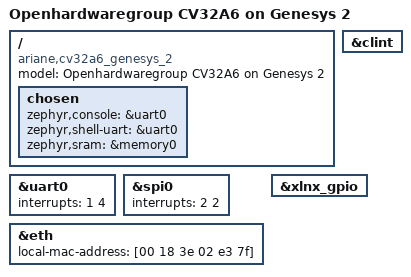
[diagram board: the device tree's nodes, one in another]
/*
 * Copyright (c) 2024 CISPA Helmholtz Center for Information Security gGmbH
 *
 * SPDX-License-Identifier: Apache-2.0
 */
/dts-v1/;

#include <openhwgroup/cv32a6.dtsi>

/ {
	model = "Openhardwaregroup CV32A6 on Genesys 2";
	compatible = "ariane,cv32a6_genesys_2";

	chosen {
		zephyr,console = &uart0;
		zephyr,shell-uart = &uart0;
		zephyr,sram = &memory0;
	};
};

&uart0 {
	status = "okay";
	// different interrupt than the CISPA version of the SoC
	interrupts = <1 4>;
};

&spi0 {
	status = "okay";
	// different interrupt than the CISPA version of the SoC
	interrupts = <2 2>;
};

&clint {
	status = "okay";
};

&eth {
	local-mac-address = [00 18 3e 02 e3 7f];
	status = "okay";
};

&xlnx_gpio {
	status = "okay";
};
